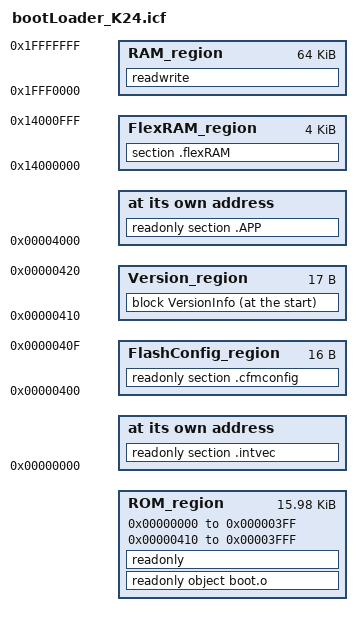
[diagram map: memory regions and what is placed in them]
/*###ICF### Section handled by ICF editor, don't touch! ****/
/*-Editor annotation file-*/
/* IcfEditorFile="$TOOLKIT_DIR$\config\ide\IcfEditor\cortex_v1_0.xml" */
/*-Specials-*/
define symbol __ICFEDIT_intvec_start__ = 0x00000000;
/*-Memory Regions-*/
define symbol __ICFEDIT_region_ROM_start__ = 0x00000000;
define symbol __ICFEDIT_region_ROM_end__   = 0x00003fff;
define symbol __ICFEDIT_region_RAM_start__ = 0x1fff0000;
define symbol __ICFEDIT_region_RAM_end__   = 0x1fffffff;
/*-Sizes-*/
define symbol __ICFEDIT_size_cstack__ = 0x800;
/**** End of ICF editor section. ###ICF###*/

define symbol DeviceSize                                             = 0x00100000;
define exported symbol __VECTOR_TABLE_ROM_START = 0x00000000;
define exported symbol __BOOT_STACK_ADDRESS     = __ICFEDIT_region_RAM_end__ + 1 - 16;

define symbol __FlashConfig_start__             = 0x00000400;
define symbol __FlashConfig_end__               = 0x0000040f;

define symbol __region_FlexRAM_start__          = 0x14000000;
define symbol __region_FlexRAM_end__            = 0x14000fff;

define memory mem with size = 4G;
define region ROM_region         = mem:[from __ICFEDIT_region_ROM_start__  to (__FlashConfig_start__ - 1)] | mem:[from (__FlashConfig_end__+1)  to __ICFEDIT_region_ROM_end__];
define region RAM_region         = mem:[from __ICFEDIT_region_RAM_start__  to __ICFEDIT_region_RAM_end__];
define region FlexRAM_region     = mem:[from __region_FlexRAM_start__      to __region_FlexRAM_end__];
define region FlashConfig_region = mem:[from __FlashConfig_start__         to __FlashConfig_end__];
define symbol VersionSize        = 0x10;
define region Version_region     = mem:[from __FlashConfig_end__ + 1       to __FlashConfig_end__ + 1 + VersionSize ];

define exported symbol app_vector   = __ICFEDIT_region_ROM_end__ + 1;
define exported symbol config       = __ICFEDIT_intvec_start__;

define exported symbol LNKR_BL_FW_VER_ADDR    = __FlashConfig_end__ + 1;   /* Location of the Bootloader FW version */
define          symbol DFW_BL_INFO_PART_size  = 0x00001000;                /* Size of the partition  NOT size of data */
define          symbol DFW_BL_INFO_PART_start = DeviceSize - DFW_BL_INFO_PART_size;
define          symbol DFW_BL_INFO_PART_end   = DeviceSize - 1;

define block VersionInfo with size = VersionSize, alignment = 4 { object version.o };

"Version": place at start of Version_region { block VersionInfo };
//keep { block VersionInfo };
keep { object version.o };

"FlexRAM": place in FlexRAM_region   { section .flexRAM };

do not initialize  { section .noinit, section .flexRAM };
initialize by copy { readwrite };
do not initialize  { section .noinit };
keep               { section .cfmconfig };

"INTVEC":
place at address mem:__ICFEDIT_intvec_start__ { readonly section .intvec };
"Flash_CFG": place in FlashConfig_region { readonly section .cfmconfig};

"ROM":
place in ROM_region  { readonly object boot.o };   /* Make boot.s first code after version info.   */
place in ROM_region  { readonly };

"RAM":
place in RAM_region  { readwrite };

"APPLICATION":
place at address mem: app_vector { readonly section .APP };
